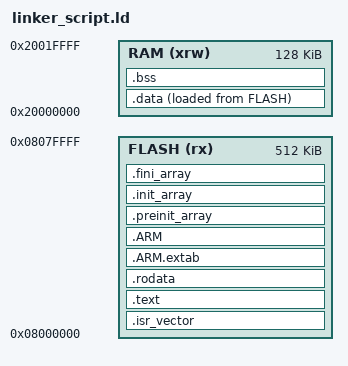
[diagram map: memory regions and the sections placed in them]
/*
*****************************************************************************
**
**  File        : LinkerScript.ld
**
**  Abstract    : Linker script for STM32F411RETx Device with
**                512KByte FLASH, 128KByte RAM
**
**                Set heap size, stack size and stack location according
**                to application requirements.
**
**                Set memory bank area and size if external memory is used.
**
**  Target      : STMicroelectronics STM32
**
**
**  Distribution: The file is distributed as is, without any warranty
**                of any kind.
**
**  (c)Copyright Ac6.
**  You may use this file as-is or modify it according to the needs of your
**  project. Distribution of this file (unmodified or modified) is not
**  permitted. Ac6 permit registered System Workbench for MCU users the
**  rights to distribute the assembled, compiled & linked contents of this
**  file as part of an application binary file, provided that it is built
**  using the System Workbench for MCU toolchain.
**
*****************************************************************************
*/

ENTRY(ResetHandler)

_FlashBaseAddr = 0x08000000;
_RamBaseAddr   = 0x20000000;
_EndStackAddr  = 0x20020000;

MEMORY
{
  FLASH (rx) : ORIGIN = _FlashBaseAddr, LENGTH = 512K
  RAM (xrw)  : ORIGIN = _RamBaseAddr, LENGTH = 128K
}

SECTIONS
{
  .isr_vector : {
    . = ALIGN(4);
    KEEP(*(.entry_vector))
    KEEP(*(.irq_vector_table))
    . = ALIGN(4);
  } > FLASH

  .text : {
    . = ALIGN(4);
    *(.text)
    *(.text*)
    *(.glue_7)
    *(.glue_7t)
    *(.eh_frame)
    KEEP (*(.init))
    KEEP (*(.fini))
    . = ALIGN(4);
    _etext = .;
  } > FLASH

  .rodata : {
    . = ALIGN(4);
    *(.rodata)
    *(.rodata*)
    . = ALIGN(4);
  } > FLASH

  .ARM.extab : {
    *(.ARM.extab* .gnu.linkonce.armextab.*)
  } > FLASH

  .ARM : {
    __exidx_start = .;
    *(.ARM.exidx*)
    __exidx_end = .;
  } > FLASH

  .preinit_array : {
    PROVIDE_HIDDEN (__preinit_array_start = .);
    KEEP (*(.preinit_array*))
    PROVIDE_HIDDEN (__preinit_array_end = .);
  } > FLASH

  .init_array : {
    PROVIDE_HIDDEN (__init_array_start = .);
    KEEP (*(SORT(.init_array.*)))
    KEEP (*(.init_array*))
    PROVIDE_HIDDEN (__init_array_end = .);
  } > FLASH

  .fini_array : {
    PROVIDE_HIDDEN (__fini_array_start = .);
    KEEP (*(SORT(.fini_array.*)))
    KEEP (*(.fini_array*))
    PROVIDE_HIDDEN (__fini_array_end = .);
  } > FLASH

  .data : {
    . = ALIGN(4);
    _sdata = .;
    *(.data)
    *(.data*)
    . = ALIGN(4);
    _edata = .;
  } > RAM AT > FLASH

  _sidata = LOADADDR(.data);

  .bss : {
    . = ALIGN(4);
    _sbss = .;
    *(.bss)
    *(.bss*)
    *(COMMON)
    . = ALIGN(4);
    _ebss = .;
  } > RAM

  /* Remove information from the standard libraries */
  /DISCARD/ : {
    libc.a ( * )
    libm.a ( * )
    libgcc.a ( * )
  }

  .ARM.attributes 0 : { *(.ARM.attributes) }
}
